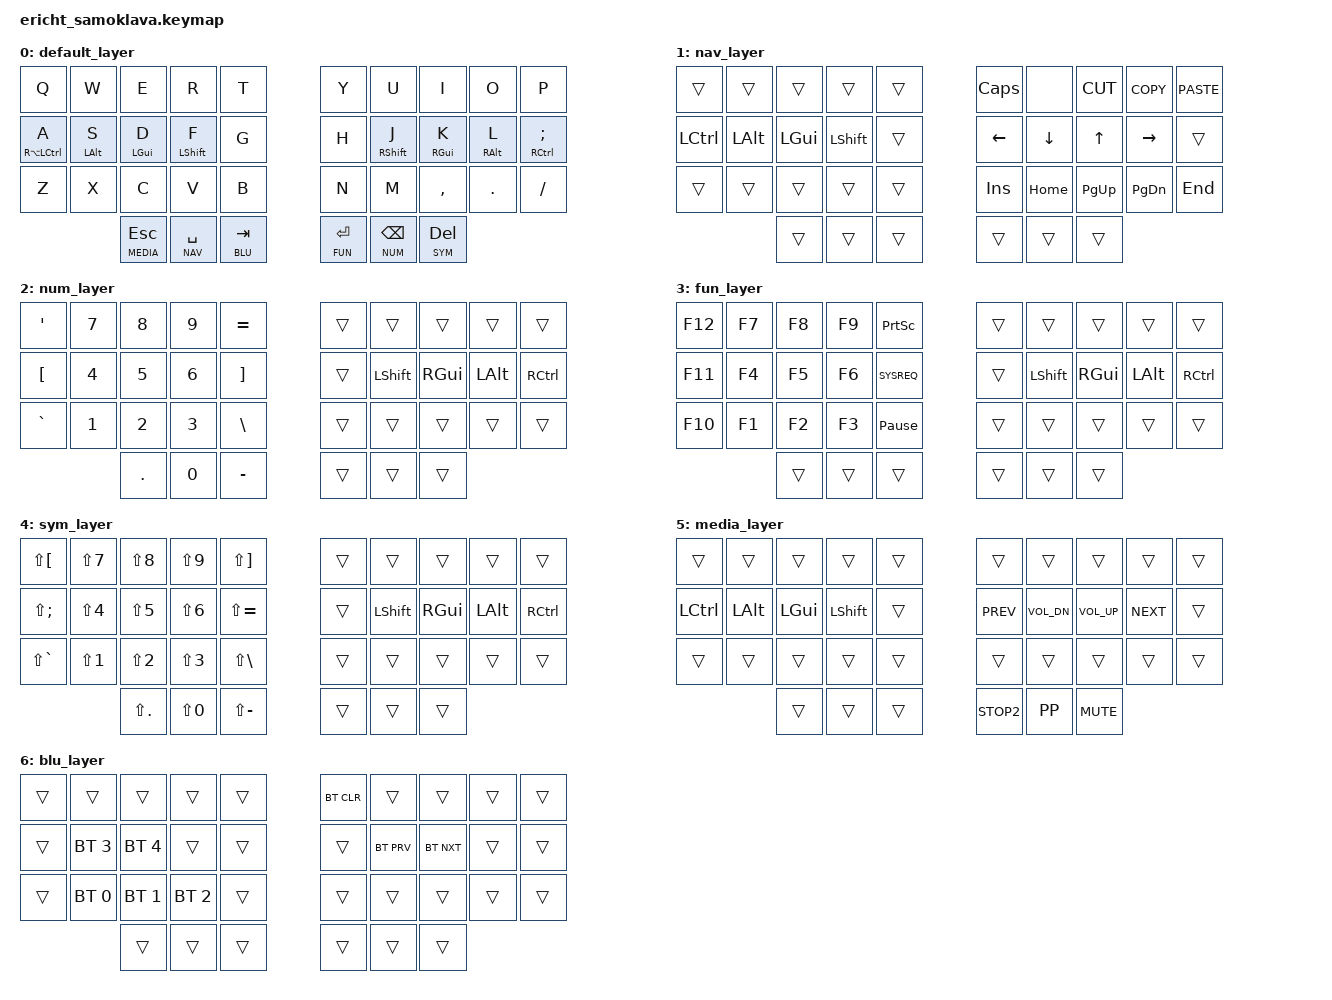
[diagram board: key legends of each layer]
 #include <behaviors.dtsi>
#include <dt-bindings/zmk/keys.h>
#include <dt-bindings/zmk/bt.h>
#include <dt-bindings/zmk/outputs.h>

#define BASE 0
#define NAV  1
#define NUM  2
#define FUN  3
#define SYM  4
#define MEDIA  5
#define BLU 6

 /*                KEY POSITIONS

          ╭────────────────────╮ ╭────────────────────╮
          │  0   1   2   3   4 │ │  5   6   7   8   9 │
          │ 10  11  12  13  14 │ │ 15  16  17  18  19 │
          │ 20  21  22  23  24 │ │ 25  26  27  28  29 │
          ╰───────╮ 30  31  32 │ │ 33  34  35 ╭───────╯
                  ╰────────────╯ ╰────────────╯        */

&mt {
    quick-tap-ms = <100>;
    global-quick-tap;
    flavor = "tap-preferred";
    tapping-term-ms = <180>;
};


/ {
    combos {
        compatible = "zmk,combos";
        cut {
            bindings = <&kp LG(X)>;
            key-positions = <1 3>;
            layers = <0>;
            timeout-ms = <40>;
        };
        copy {
            bindings = <&kp LG(C)>;
            key-positions = <1 2>;
            layers = <0>;
            timeout-ms = <40>;
        };

        paste {
            bindings = <&kp LG(V)>;
            key-positions = <2 3>;
            layers = <0>;
            timeout-ms = <40>;
        };

        leftParet {
            bindings = <&kp LEFT_PARENTHESIS>;
            key-positions = <6 7>;
            layers = <0>;
        };

        rightParet {
            bindings = <&kp RIGHT_PARENTHESIS>;
            key-positions = <7 8>;
            layers = <0>;
        };

        minusCombo {
            bindings = <&kp MINUS>;
            key-positions = <32 33>;
            layers = <0>;
        };

        capslock {
            bindings = <&caps_word>;
            key-positions = <4 5>;
            layers = <0>;
        };

        undo {
            bindings = <&kp LG(Z)>;
            key-positions = <22 21>;
            layers = <0>;
            timeout-ms = <40>;
        };

        redo {
            bindings = <&kp LG(Y)>;
            key-positions = <23 22>;
            layers = <0>;
            timeout-ms = <40>;
        };

        printscreen {
            bindings = <&kp LG(LS(N5))>;
            key-positions = <1 2 3>;
            layers = <0>;
            timeout-ms = <40>;
        };

    };
    behaviors {
        rht: repeatHoldTap {
            compatible = "zmk,behavior-hold-tap";
            label = "REPEATHOLDTAP";
            bindings =
                <&mo>,
                <&kp>;

            #binding-cells = <2>;
            flavor = "tap-preferred";
            tapping-term-ms = <150>;
            quick-tap-ms = <200>;
        };
    };


	keymap {
		compatible = "zmk,keymap";

 default_layer {
            bindings = <
&kp Q                 &kp W        &kp E          &kp R        &kp T    &kp Y  &kp U        &kp I         &kp O        &kp P
&mt RA(LEFT_CONTROL) A&mt LALT S   &mt LGUI D     &mt LSHFT F  &kp G    &kp H  &mt RSHFT J  &mt RGUI K    &mt RALT L   &mt RIGHT_CONTROL SEMICOLON
&kp Z                 &kp X        &kp C          &kp V        &kp B    &kp N  &kp M        &kp COMMA     &kp DOT      &kp SLASH
&lt MEDIA ESC           &rht NAV SPACE  &lt BLU TAB                  &lt FUN RET &rht NUM BSPC   &lt SYM DEL
            >;

        };


        nav_layer {
            bindings = <
&trans          &trans    &trans        &trans       &trans    &kp CAPSLOCK  &none  &kp K_CUT  &kp K_COPY  &kp K_PASTE
&kp LEFT_CONTROL	&kp LALT  &kp LEFT_GUI  &kp LSHFT    &trans    &kp LEFT      &kp DOWN    &kp UP     &kp RIGHT   &trans
&trans         		&trans    &trans        &trans       &trans    &kp INSERT    &kp HOME    &kp PG_UP  &kp PG_DN   &kp END
 			&trans          &trans    &trans                                    &trans    &trans    &trans
            >;

        };

        num_layer {
            bindings = <
&kp APOSTROPHE        &kp N7  &kp N8     &kp N9       &kp EQUAL            &trans  &trans       &trans         &trans    &trans
&kp LEFT_BRACKET&kp N4  &kp N5     &kp N6       &kp RIGHT_BRACKET    &trans  &kp LSHFT    &kp RIGHT_GUI  &kp LALT  &kp RIGHT_CONTROL
&kp GRAVE       &kp N1  &kp N2     &kp N3       &kp BSLH             &trans  &trans       &trans         &trans    &trans
			&kp PERIOD      &kp N0  &kp MINUS                                &trans         &trans    &trans
            >;

        };

        fun_layer {
            bindings = <
&kp F12&kp F7     &kp F8   &kp F9       &kp PSCRN          &trans  &trans       &trans         &trans    &trans
&kp F11&kp F4     &kp F5   &kp F6       &kp SYSREQ         &trans  &kp LSHFT    &kp RIGHT_GUI  &kp LALT  &kp RIGHT_CONTROL
&kp F10&kp F1     &kp F2   &kp F3       &kp PAUSE_BREAK    &trans  &trans       &trans         &trans    &trans
&trans &trans  &trans                             &trans         &trans    &trans
            >;
        };

        sym_layer {
            bindings = <
&kp LS(LBKT)  &kp LS(N7)  &kp LS(N8)     &kp LS(N9)   &kp LS(RBKT)     &trans  &trans       &trans    &trans    &trans
&kp LS(SEMI)  &kp LS(N4)  &kp LS(N5)     &kp LS(N6)   &kp LS(EQUAL)    &trans  &kp LSHFT    &kp RGUI  &kp LALT  &kp RIGHT_CONTROL
&kp LS(GRAVE) &kp LS(N1)  &kp LS(N2)     &kp LS(N3)   &kp LS(BSLH)     &trans  &trans       &trans    &trans    &trans
&kp LS(PERIOD)&kp LS(N0)  &kp LS(MINUS)                             &trans    &trans    &trans
            >;
        };

        media_layer {
            bindings = <
&trans          &trans    &trans        &trans       &trans    &trans      &trans        &trans        &trans      &trans
&kp LEFT_CONTROL&kp LALT  &kp LEFT_GUI  &kp LSHFT    &trans    &kp K_PREV  &kp K_VOL_DN  &kp K_VOL_UP  &kp K_NEXT  &trans
&trans          &trans    &trans        &trans       &trans    &trans      &trans        &trans        &trans      &trans
&trans          &trans    &trans                                   &kp K_STOP2   &kp K_PP    &kp K_MUTE
            >;
        };

        blu_layer {
            bindings = <
&trans&trans        &trans        &trans        &trans    &bt BT_CLR  &trans      &trans      &trans  &trans
&trans&bt BT_SEL 3  &bt BT_SEL 4  &trans        &trans    &trans      &bt BT_PRV  &bt BT_NXT  &trans  &trans
&trans&bt BT_SEL 0  &bt BT_SEL 1  &bt BT_SEL 2  &trans    &trans      &trans      &trans      &trans  &trans
&trans&trans        &trans                                       &trans      &trans  &trans
            >;

		};
	};
};
